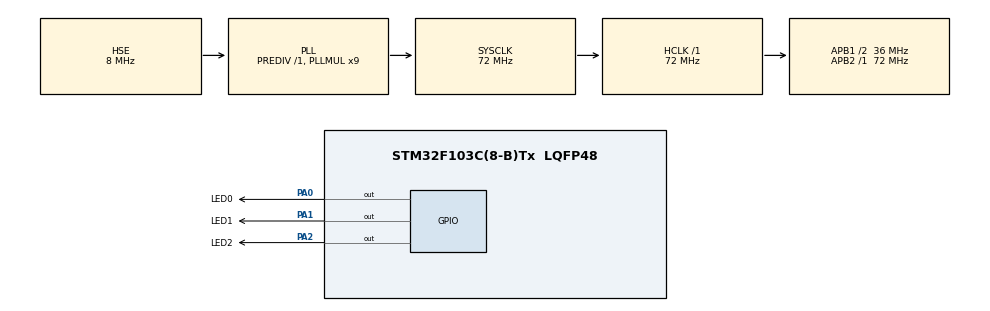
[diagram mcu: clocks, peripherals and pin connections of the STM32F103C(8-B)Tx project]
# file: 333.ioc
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Mcu.Family=STM32F1
Mcu.Name=STM32F103C(8-B)Tx
Mcu.Package=LQFP48
NVIC.PriorityGroup=NVIC_PRIORITYGROUP_4
PA0-WKUP.GPIO_Label=LED0
PA0-WKUP.PinState=GPIO_PIN_RESET
PA0-WKUP.Signal=GPIO_Output
PA1.GPIO_Label=LED1
PA1.Signal=GPIO_Output
PA13.Mode=Serial_Wire
PA13.Signal=SYS_JTMS-SWDIO
PA14.Mode=Serial_Wire
PA14.Signal=SYS_JTCK-SWCLK
PA2.GPIO_Label=LED2
PA2.Signal=GPIO_Output
PC14-OSC32_IN.Mode=LSE-External-Oscillator
PC14-OSC32_IN.Signal=RCC_OSC32_IN
PC15-OSC32_OUT.Mode=LSE-External-Oscillator
PC15-OSC32_OUT.Signal=RCC_OSC32_OUT
PD0-OSC_IN.Mode=HSE-External-Oscillator
PD0-OSC_IN.Signal=RCC_OSC_IN
PD1-OSC_OUT.Mode=HSE-External-Oscillator
PD1-OSC_OUT.Signal=RCC_OSC_OUT
ProjectManager.HeapSize=0x200
ProjectManager.StackSize=0x400
ProjectManager.TargetToolchain=STM32CubeIDE
RCC.AHBFreq_Value=72000000
RCC.APB1CLKDivider=RCC_HCLK_DIV2
RCC.APB1Freq_Value=36000000
RCC.APB1TimFreq_Value=72000000
RCC.APB2Freq_Value=72000000
RCC.APB2TimFreq_Value=72000000
RCC.HCLKFreq_Value=72000000
RCC.PLLMUL=RCC_PLL_MUL9
RCC.PLLSourceVirtual=RCC_PLLSOURCE_HSE
RCC.SYSCLKFreq_VALUE=72000000
RCC.SYSCLKSource=RCC_SYSCLKSOURCE_PLLCLK
RCC.USBFreq_Value=72000000
board=custom

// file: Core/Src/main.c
/* USER CODE BEGIN Header */
/**
  ******************************************************************************
  * @file           : main.c
  * @brief          : Main program body
  ******************************************************************************
  * @attention
  *
  * Copyright (c) 2026 STMicroelectronics.
  * All rights reserved.
  *
  * This software is licensed under terms that can be found in the LICENSE file
  * in the root directory of this software component.
  * If no LICENSE file comes with this software, it is provided AS-IS.
  *
  ******************************************************************************
  */
/* USER CODE END Header */
#include "main.h"
#include "gpio.h"

/* USER CODE BEGIN PTD */
/* 一颗 LED 的端口 + 引脚 */
typedef struct {
  GPIO_TypeDef *port;
  uint16_t      pin;
} led_t;
/* USER CODE END PTD */

/* USER CODE BEGIN PD */
/* 流水灯切换间隔：500 ms */
#define LED_STEP_MS 500u
/* USER CODE END PD */

/* USER CODE BEGIN PV */
/* LED0/LED1/LED2 的宏由 CubeMX 根据 User Label 生成在 main.h 里 */
static const led_t LEDS[] = {
  { LED0_GPIO_Port, LED0_Pin },
  { LED1_GPIO_Port, LED1_Pin },
  { LED2_GPIO_Port, LED2_Pin },
};
#define LED_COUNT (sizeof(LEDS) / sizeof(LEDS[0]))

static uint32_t led_index = 0;   /* 当前点亮的灯 */
static uint32_t led_tick  = 0;   /* 上次切换时的时间戳（ms） */
/* USER CODE END PV */

void SystemClock_Config(void);

int main(void)
{

  /* MCU Configuration--------------------------------------------------------*/

  /* Reset of all peripherals, Initializes the Flash interface and the Systick. */
  HAL_Init();

  /* Configure the system clock */
  SystemClock_Config();

  /* Initialize all configured peripherals */
  MX_GPIO_Init();
  /* USER CODE BEGIN 2 */
  /* 上电先点亮 LED0，并记录起始时间戳 */
  HAL_GPIO_WritePin(LEDS[0].port, LEDS[0].pin, GPIO_PIN_SET);
  led_index = 0;
  led_tick  = HAL_GetTick();
  /* USER CODE END 2 */

  /* Infinite loop */
  while (1)
  {

    /* USER CODE BEGIN 3 */
    /* 非阻塞延时：只比较 SysTick 时间戳，不做死等 */
    if (HAL_GetTick() - led_tick >= LED_STEP_MS) {
      led_tick += LED_STEP_MS;   /* 固定步长累加，长时间运行也不会累积漂移 */

      /* 熄灭当前灯，点亮下一颗，循环往复 */
      HAL_GPIO_WritePin(LEDS[led_index].port, LEDS[led_index].pin, GPIO_PIN_RESET);
      led_index = (led_index + 1) % LED_COUNT;
      HAL_GPIO_WritePin(LEDS[led_index].port, LEDS[led_index].pin, GPIO_PIN_SET);
    }

    /* 这里可以放其它任务，不会被上面的延时阻塞 */
  }
  /* USER CODE END 3 */
}

void SystemClock_Config(void)
{
  RCC_OscInitTypeDef RCC_OscInitStruct = {0};
  RCC_ClkInitTypeDef RCC_ClkInitStruct = {0};

  /** Initializes the RCC Oscillators according to the specified parameters
  * in the RCC_OscInitTypeDef structure.
  */
  RCC_OscInitStruct.OscillatorType = RCC_OSCILLATORTYPE_HSE;
  RCC_OscInitStruct.HSEState = RCC_HSE_ON;
  RCC_OscInitStruct.HSEPredivValue = RCC_HSE_PREDIV_DIV1;
  RCC_OscInitStruct.HSIState = RCC_HSI_ON;
  RCC_OscInitStruct.PLL.PLLState = RCC_PLL_ON;
  RCC_OscInitStruct.PLL.PLLSource = RCC_PLLSOURCE_HSE;
  RCC_OscInitStruct.PLL.PLLMUL = RCC_PLL_MUL9;
  if (HAL_RCC_OscConfig(&RCC_OscInitStruct) != HAL_OK)
  {
    Error_Handler();
  }

  /** Initializes the CPU, AHB and APB buses clocks
  */
  RCC_ClkInitStruct.ClockType = RCC_CLOCKTYPE_HCLK|RCC_CLOCKTYPE_SYSCLK
                              |RCC_CLOCKTYPE_PCLK1|RCC_CLOCKTYPE_PCLK2;
  RCC_ClkInitStruct.SYSCLKSource = RCC_SYSCLKSOURCE_PLLCLK;
  RCC_ClkInitStruct.AHBCLKDivider = RCC_SYSCLK_DIV1;
  RCC_ClkInitStruct.APB1CLKDivider = RCC_HCLK_DIV2;
  RCC_ClkInitStruct.APB2CLKDivider = RCC_HCLK_DIV1;

  if (HAL_RCC_ClockConfig(&RCC_ClkInitStruct, FLASH_LATENCY_2) != HAL_OK)
  {
    Error_Handler();
  }
}

void Error_Handler(void)
{
  __disable_irq();
  while (1)
  {
  }
}
